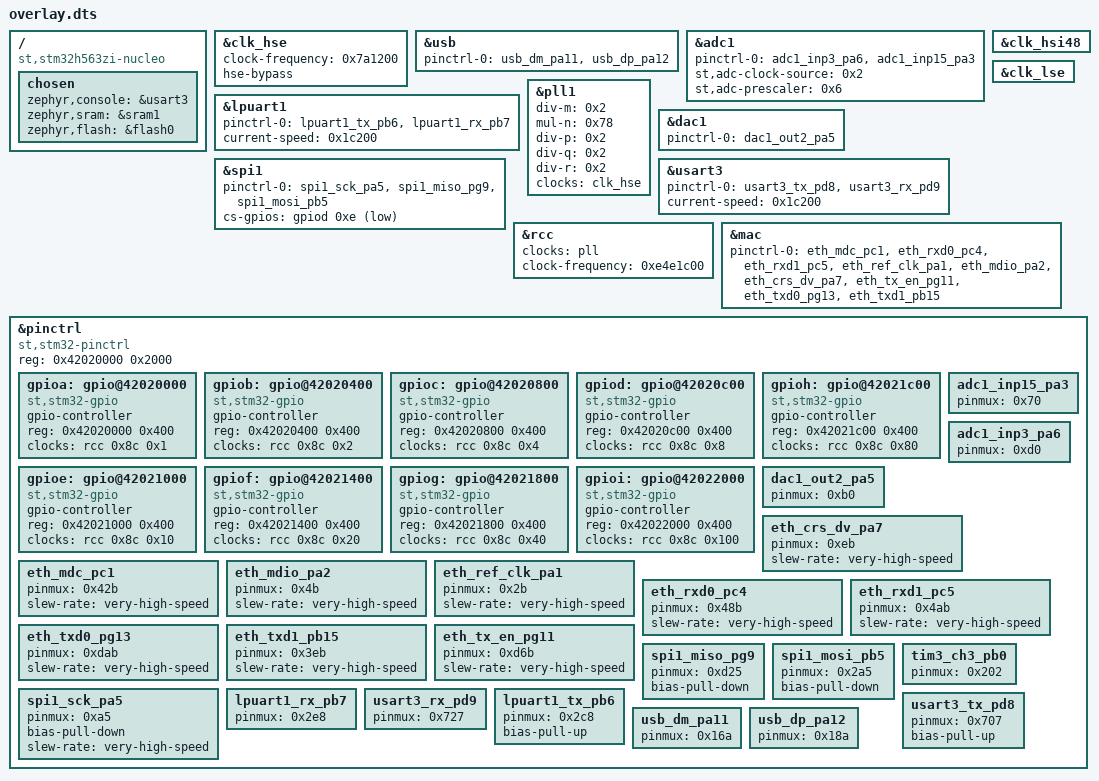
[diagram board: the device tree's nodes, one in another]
/ {
	compatible = "st,stm32h563zi-nucleo";
	chosen {
		zephyr,console = &usart3;
		zephyr,sram = &sram1;
		zephyr,flash = &flash0;
	};
};
&clk_hse{
	status = "okay";
	clock-frequency = < 0x7a1200 >;
	hse-bypass;
};
&usb{
	status = "okay";
	pinctrl-0 = < &usb_dm_pa11 &usb_dp_pa12 >;
	pinctrl-names = "default";
};
&adc1{
	status = "okay";
	pinctrl-0 = < &adc1_inp3_pa6 &adc1_inp15_pa3 >;
	pinctrl-names = "default";
	st,adc-clock-source = < 0x2 >;
	st,adc-prescaler = < 0x6 >;
};
&lpuart1{
	status = "okay";
	pinctrl-0 = < &lpuart1_tx_pb6 &lpuart1_rx_pb7 >;
	pinctrl-names = "default";
	current-speed = < 0x1c200 >;
};
&pll1{
	status = "okay";
	div-m = < 0x2 >;
	mul-n = < 0x78 >;
	div-p = < 0x2 >;
	div-q = < 0x2 >;
	div-r = < 0x2 >;
	clocks = < &clk_hse >;
};
&clk_hsi48{
	status = "okay";
};
&dac1{
	status = "okay";
	pinctrl-0 = < &dac1_out2_pa5 >;
	pinctrl-names = "default";
};
&clk_lse{
	status = "okay";
};
&spi1{
	status = "okay";
	pinctrl-0 = < &spi1_sck_pa5 &spi1_miso_pg9 &spi1_mosi_pb5 >;
	pinctrl-names = "default";
	cs-gpios = < &gpiod 0xe 0x11 >;
};
&usart3{
	status = "okay";
	pinctrl-0 = < &usart3_tx_pd8 &usart3_rx_pd9 >;
	pinctrl-names = "default";
	current-speed = < 0x1c200 >;
};
&rcc{
	clocks = < &pll >;
	clock-frequency = < 0xe4e1c00 >;
};
&mac{
	status = "okay";
	pinctrl-0 = < &eth_mdc_pc1 &eth_rxd0_pc4 &eth_rxd1_pc5 &eth_ref_clk_pa1 &eth_mdio_pa2 &eth_crs_dv_pa7 &eth_tx_en_pg11 &eth_txd0_pg13 &eth_txd1_pb15 >;
	pinctrl-names = "default";
};
&pinctrl{
	compatible = "st,stm32-pinctrl";
	#address-cells = < 0x1 >;
	#size-cells = < 0x1 >;
	reg = < 0x42020000 0x2000 >;
	gpioa: gpio@42020000 {
		compatible = "st,stm32-gpio";
		gpio-controller;
		#gpio-cells = < 0x2 >;
		reg = < 0x42020000 0x400 >;
		clocks = < &rcc 0x8c 0x1 >;
	};
	gpiob: gpio@42020400 {
		compatible = "st,stm32-gpio";
		gpio-controller;
		#gpio-cells = < 0x2 >;
		reg = < 0x42020400 0x400 >;
		clocks = < &rcc 0x8c 0x2 >;
	};
	gpioc: gpio@42020800 {
		compatible = "st,stm32-gpio";
		gpio-controller;
		#gpio-cells = < 0x2 >;
		reg = < 0x42020800 0x400 >;
		clocks = < &rcc 0x8c 0x4 >;
	};
	gpiod: gpio@42020c00 {
		compatible = "st,stm32-gpio";
		gpio-controller;
		#gpio-cells = < 0x2 >;
		reg = < 0x42020c00 0x400 >;
		clocks = < &rcc 0x8c 0x8 >;
	};
	gpioh: gpio@42021c00 {
		compatible = "st,stm32-gpio";
		gpio-controller;
		#gpio-cells = < 0x2 >;
		reg = < 0x42021c00 0x400 >;
		clocks = < &rcc 0x8c 0x80 >;
	};
	gpioe: gpio@42021000 {
		compatible = "st,stm32-gpio";
		gpio-controller;
		#gpio-cells = < 0x2 >;
		reg = < 0x42021000 0x400 >;
		clocks = < &rcc 0x8c 0x10 >;
	};
	gpiof: gpio@42021400 {
		compatible = "st,stm32-gpio";
		gpio-controller;
		#gpio-cells = < 0x2 >;
		reg = < 0x42021400 0x400 >;
		clocks = < &rcc 0x8c 0x20 >;
	};
	gpiog: gpio@42021800 {
		compatible = "st,stm32-gpio";
		gpio-controller;
		#gpio-cells = < 0x2 >;
		reg = < 0x42021800 0x400 >;
		clocks = < &rcc 0x8c 0x40 >;
	};
	gpioi: gpio@42022000 {
		compatible = "st,stm32-gpio";
		gpio-controller;
		#gpio-cells = < 0x2 >;
		reg = < 0x42022000 0x400 >;
		clocks = < &rcc 0x8c 0x100 >;
	};
	adc1_inp15_pa3: adc1_inp15_pa3 {
		pinmux = < 0x70 >;
	};
	adc1_inp3_pa6: adc1_inp3_pa6 {
		pinmux = < 0xd0 >;
	};
	dac1_out2_pa5: dac1_out2_pa5 {
		pinmux = < 0xb0 >;
	};
	eth_crs_dv_pa7: eth_crs_dv_pa7 {
		pinmux = < 0xeb >;
		slew-rate = "very-high-speed";
	};
	eth_mdc_pc1: eth_mdc_pc1 {
		pinmux = < 0x42b >;
		slew-rate = "very-high-speed";
	};
	eth_mdio_pa2: eth_mdio_pa2 {
		pinmux = < 0x4b >;
		slew-rate = "very-high-speed";
	};
	eth_ref_clk_pa1: eth_ref_clk_pa1 {
		pinmux = < 0x2b >;
		slew-rate = "very-high-speed";
	};
	eth_rxd0_pc4: eth_rxd0_pc4 {
		pinmux = < 0x48b >;
		slew-rate = "very-high-speed";
	};
	eth_rxd1_pc5: eth_rxd1_pc5 {
		pinmux = < 0x4ab >;
		slew-rate = "very-high-speed";
	};
	eth_txd0_pg13: eth_txd0_pg13 {
		pinmux = < 0xdab >;
		slew-rate = "very-high-speed";
	};
	eth_txd1_pb15: eth_txd1_pb15 {
		pinmux = < 0x3eb >;
		slew-rate = "very-high-speed";
	};
	eth_tx_en_pg11: eth_tx_en_pg11 {
		pinmux = < 0xd6b >;
		slew-rate = "very-high-speed";
	};
	spi1_miso_pg9: spi1_miso_pg9 {
		pinmux = < 0xd25 >;
		bias-pull-down;
	};
	spi1_mosi_pb5: spi1_mosi_pb5 {
		pinmux = < 0x2a5 >;
		bias-pull-down;
	};
	spi1_sck_pa5: spi1_sck_pa5 {
		pinmux = < 0xa5 >;
		bias-pull-down;
		slew-rate = "very-high-speed";
	};
	tim3_ch3_pb0: tim3_ch3_pb0 {
		pinmux = < 0x202 >;
	};
	lpuart1_rx_pb7: lpuart1_rx_pb7 {
		pinmux = < 0x2e8 >;
	};
	usart3_rx_pd9: usart3_rx_pd9 {
		pinmux = < 0x727 >;
	};
	lpuart1_tx_pb6: lpuart1_tx_pb6 {
		pinmux = < 0x2c8 >;
		bias-pull-up;
	};
	usart3_tx_pd8: usart3_tx_pd8 {
		pinmux = < 0x707 >;
		bias-pull-up;
	};
	usb_dm_pa11: usb_dm_pa11 {
		pinmux = < 0x16a >;
	};
	usb_dp_pa12: usb_dp_pa12 {
		pinmux = < 0x18a >;
	};
};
